AUTOSAR XML (schema 00046)
package /SWC
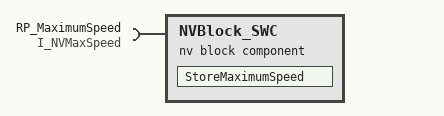
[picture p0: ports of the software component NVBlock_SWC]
  nv block sw component type NVBlock_SWC
    require port RP_MaximumSpeed: required-interface=I_NVMaxSpeed
    behavior IB_NVBlockBehavior
      timing event DrivingCycleEndEvent: period=0
      runnable-entities:
        runnable StoreMaximumSpeed: event-to-runnable-mapping=event=DrivingCycleEndEvent
